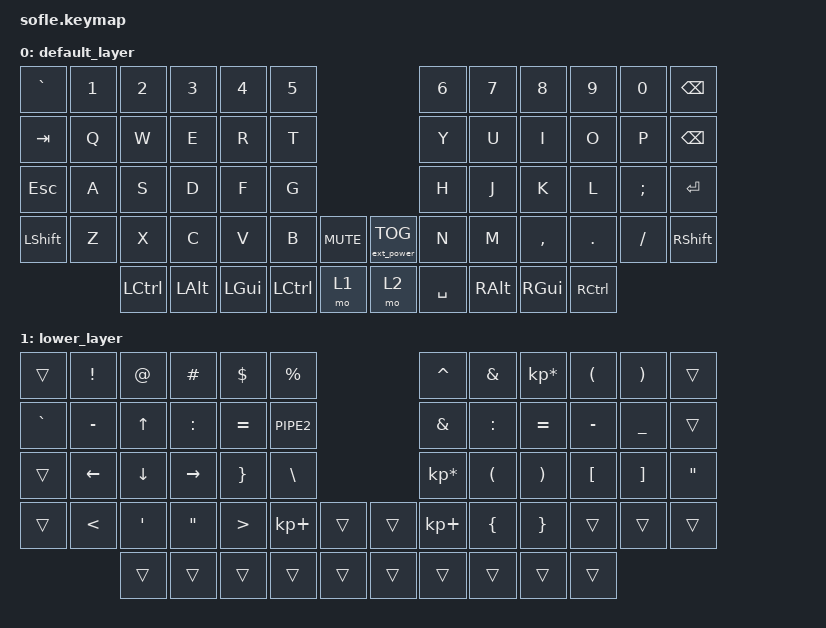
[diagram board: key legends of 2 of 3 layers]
/*
 * Copyright (c) 2020 The ZMK Contributors
 *
 * SPDX-License-Identifier: MIT
 */

#include <behaviors.dtsi>
#include <dt-bindings/zmk/keys.h>
#include <dt-bindings/zmk/bt.h>
#include <dt-bindings/zmk/ext_power.h>

/ {
    keymap {
        compatible = "zmk,keymap";

        default_layer {
// ------------------------------------------------------------------------------------------------------------
// | GRAVE |  1  |  2  |  3   |  4   |  5   |                         |  6   |  7    |  8    |  9   |   0   | BKSPC |
// |  TAB  |  Q  |  W  |  E   |  R   |  T   |                         |  Y   |  U    |  I    |  O   |   P   | BKSPC |
// |  ESC  |  A  |  S  |  D   |  F   |  G   |                         |  H   |  J    |  K    |  L   |   ;   | ENTER |
// | SHIFT |  Z  |  X  |  C   |  V   |  B   |  MUTE  |        | ExtPw |  N   |  M    |  ,    |  .   |   /   | SHIFT |
//             | LCTRL | ALT  | LGUI | RAISE|  LCTRL |        | CTRL  | LOWER| SPACE | ALT   | GUI  |
            bindings = <
&kp GRAVE &kp N1 &kp N2   &kp N3   &kp N4    &kp N5                              &kp N6 &kp N7    &kp N8    &kp N9   &kp N0   &kp BSPC
&kp TAB   &kp Q  &kp W    &kp E    &kp R     &kp T                               &kp Y  &kp U     &kp I     &kp O    &kp P    &kp BSPC
&kp ESC   &kp A  &kp S    &kp D    &kp F     &kp G                               &kp H  &kp J     &kp K     &kp L    &kp SEMI &kp RET
&kp LSHFT &kp Z  &kp X    &kp C    &kp V     &kp B  &kp C_MUTE &ext_power EP_TOG &kp N  &kp M     &kp COMMA &kp DOT  &kp FSLH &kp RSHFT
                 &kp LCTRL &kp LALT &kp LGUI &kp LCTRL &mo 1      &mo 2 &kp SPACE  &kp RALT  &kp RGUI &kp RCTRL
            >;
 
            sensor-bindings = <&inc_dec_kp C_VOL_UP C_VOL_DN &inc_dec_kp PG_UP PG_DN>;
        };


        lower_layer {
// TODO: Some binds are waiting for shifted keycode support.
//                                                  |\
// ------------------------------------------------------------------------------------------------------------
// |       |  !  |  @  |  #   |  $   |  %   |                   |   ^  |   &   |   *   |   (  |   )   |  BSCP |
// | `     |  -  |  UP |   :  |  =   |  |   |                   |   &  |   :   |   =   |   -  |    _  |  F12  |
// |       |LEFT | DOWN| RIGHT|  }   |  \   |                   |   *  |  (    |  )    | [    |   ]   |   "   |
// |       |  <  |  '  |  "   |  >   |  +   |        |  |       |  +   |  {    |  }    |  .   |   /   |       |
//               |     |      |      |      |        |  |       |      |       |       |      |
            bindings = <
&trans    &kp EXCL  &kp AT    &kp HASH   &kp DLLR  &kp PRCNT                     &kp CARET       &kp AMPS  &kp KP_MULTIPLY &kp LPAR  &kp RPAR   &trans
&kp GRAVE &kp MINUS &kp UP    &kp COLON  &kp EQUAL &kp PIPE2                     &kp AMPS        &kp COLON &kp EQUAL       &kp MINUS &kp UNDER  &trans
&trans    &kp LEFT  &kp DOWN  &kp RIGHT  &kp RBRC  &kp BSLH                      &kp KP_MULTIPLY &kp LPAR  &kp RPAR        &kp LBKT  &kp RBKT   &kp DQT
&trans    &kp LT    &kp APOS  &kp DQT    &kp GT    &kp KP_PLUS  &trans   &trans  &kp KP_PLUS     &kp LBRC  &kp RBRC        &trans    &trans     &trans
                    &trans    &trans     &trans    &trans       &trans   &trans  &trans          &trans    &trans          &trans
            >;
 
            sensor-bindings = <&inc_dec_kp C_VOL_UP C_VOL_DN &inc_dec_kp PG_UP PG_DN>;
        };

        raise_layer {
// ------------------------------------------------------------------------------------------------------------
// |  F1 |  F2  |  F3  |  F4   |  F5   |  F6  |                |  F7  |  F8  |   F9  |  F10 |  F11  |  F12  |
// | BTC | BT1  | BT2  |  BT3  |  BT4  |  BT5 |                |      |      |       |      |       |       |
// |     |      |      |       |       |      |                | LEFT |  v   |  ^    | RIGHT|       |       |
// |     |      |      |       |       |      |      |  |      |      |      |       |      |       |       |
//              |      |       |       |      |      |  |      |      |      |       |      |
            bindings = <
&kp F1       &kp F2       &kp F3         &kp F4        &kp F5        &kp F6                       &kp F7    &kp F8    &kp F9    &kp F10  &kp F11  &kp F12
&bt BT_CLR   &bt BT_SEL 0 &bt BT_SEL 1   &bt BT_SEL 2  &bt BT_SEL 3  &bt BT_SEL 4                     &trans    &trans    &trans    &trans    &trans   &trans
&trans       &trans       &trans         &trans        &trans        &trans                           &kp LEFT  &kp DOWN  &kp UP    &kp RIGHT &trans   &trans
&trans       &trans       &trans         &trans        &trans        &trans        &trans   &trans    &trans    &trans    &trans    &trans    &trans   &trans
                          &trans         &trans        &trans        &trans        &trans   &trans    &trans    &trans    &trans    &trans    &trans   &trans
            >;
 
            sensor-bindings = <&inc_dec_kp C_VOL_UP C_VOL_DN &inc_dec_kp PG_UP PG_DN>;
        };
    };
};
